AUTOSAR XML (schema 00046)
package /ShortName_1
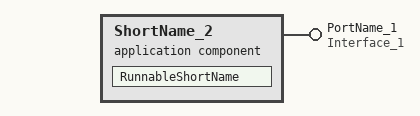
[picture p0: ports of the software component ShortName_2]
  application sw component type ShortName_2
    provide port PortName_1: provided-interface=Interface_1
    behavior IB_Name
      runnable RunnableShortName
  sender receiver interface Interface_1
    data VDPName_1: category=VALUE, implementation-data-type=uint8
  sender receiver interface Interface_2
    data VDPName_2: category=VALUE, implementation-data-type=uint8
